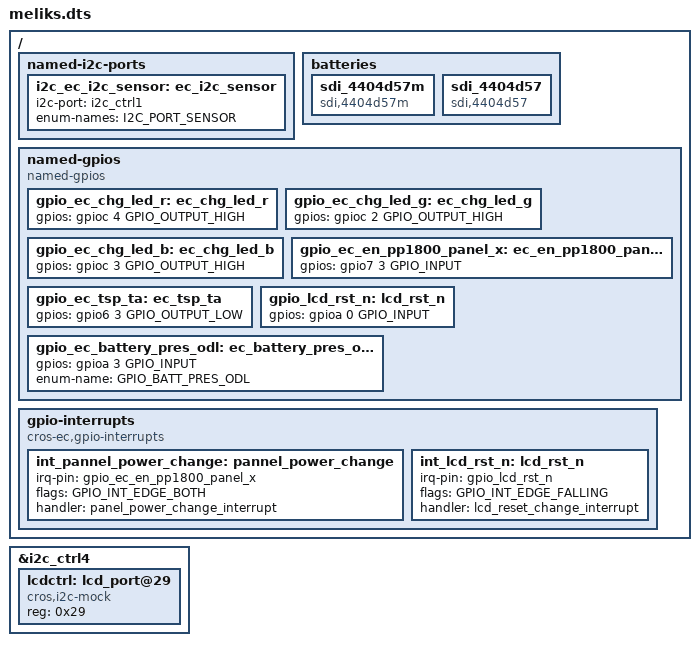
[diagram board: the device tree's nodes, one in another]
/* Copyright 2025 The ChromiumOS Authors
 * Use of this source code is governed by a BSD-style license that can be
 * found in the LICENSE file.
 */

/ {
	named-i2c-ports {
		i2c_ec_i2c_sensor: ec_i2c_sensor {
			i2c-port = <&i2c_ctrl1>;
			enum-names = "I2C_PORT_SENSOR";
		};
	};

	batteries {
		sdi_4404d57m {
			compatible = "sdi,4404d57m", "battery-smart";
		};

		sdi_4404d57 {
			compatible = "sdi,4404d57", "battery-smart";
		};
	};

	named-gpios {
		compatible = "named-gpios";

		gpio_ec_chg_led_r: ec_chg_led_r {
			gpios = <&gpioc 4 GPIO_OUTPUT_HIGH>;
		};
		gpio_ec_chg_led_g: ec_chg_led_g {
			gpios = <&gpioc 2 GPIO_OUTPUT_HIGH>;
		};
		gpio_ec_chg_led_b: ec_chg_led_b {
			gpios = <&gpioc 3 GPIO_OUTPUT_HIGH>;
		};
		gpio_ec_en_pp1800_panel_x: ec_en_pp1800_panel_x {
			gpios = <&gpio7 3 GPIO_INPUT>;
		};
		gpio_ec_tsp_ta: ec_tsp_ta {
			gpios = <&gpio6 3 GPIO_OUTPUT_LOW>;
		};
		gpio_lcd_rst_n: lcd_rst_n {
			gpios = <&gpioa 0 GPIO_INPUT>;
		};
		gpio_ec_battery_pres_odl: ec_battery_pres_odl {
			gpios = <&gpioa 3 GPIO_INPUT>;
			enum-name = "GPIO_BATT_PRES_ODL";
		};
	};

	gpio-interrupts {
		compatible = "cros-ec,gpio-interrupts";

		int_pannel_power_change: pannel_power_change {
			irq-pin = <&gpio_ec_en_pp1800_panel_x>;
			flags = <GPIO_INT_EDGE_BOTH>;
			handler = "panel_power_change_interrupt";
		};
		int_lcd_rst_n: lcd_rst_n {
			irq-pin = <&gpio_lcd_rst_n>;
			flags = <GPIO_INT_EDGE_FALLING>;
			handler = "lcd_reset_change_interrupt";
		};
	};
};

&i2c_ctrl4 {
	status = "okay";

	lcdctrl: lcd_port@29 {
		compatible = "cros,i2c-mock";
		reg = <0x29>;
	};
};
